AUTOSAR XML (schema 4-2-2)
package /ASW_COM_Package
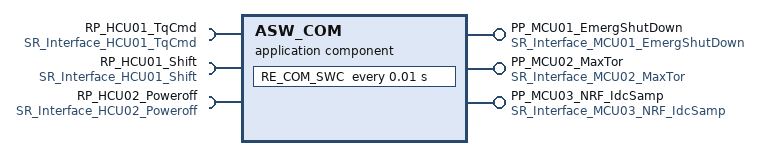
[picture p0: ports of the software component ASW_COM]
  application sw component type ASW_COM
    provide port PP_MCU01_EmergShutDown: provided-interface=SR_Interface_MCU01_EmergShutDown
    provide port PP_MCU02_MaxTor: provided-interface=SR_Interface_MCU02_MaxTor
    provide port PP_MCU03_NRF_IdcSamp: provided-interface=SR_Interface_MCU03_NRF_IdcSamp
    require port RP_HCU01_TqCmd: required-interface=SR_Interface_HCU01_TqCmd, nonqueued-receiver-com-spec{data-element=DE_TqCmd, alive-timeout=0.3}
    require port RP_HCU01_Shift: required-interface=SR_Interface_HCU01_Shift, nonqueued-receiver-com-spec{data-element=DE_Shift, alive-timeout=0.3}
    require port RP_HCU02_Poweroff: required-interface=SR_Interface_HCU02_Poweroff, nonqueued-receiver-com-spec{data-element=DE_Poweroff, alive-timeout=0.3}
    internal behavior IB_ASW_COM
      timing event TE_RE_COM_SWC_10ms: start-on-event=RE_COM_SWC, period=0.01
      runnable RE_COM_SWC: minimum-start-interval=0.01
        data-read-access:
          access VA_READ_HCU01_TqCmd: accessed-variable=RP_HCU01_TqCmd.DE_TqCmd
          access VA_READ_HCU01_Shift: accessed-variable=RP_HCU01_Shift.DE_Shift
          access VA_READ_HCU02_Poweroff: accessed-variable=RP_HCU02_Poweroff.DE_Poweroff
        data-write-access:
          access VA_WRITE_MCU01_EmergShutDown: accessed-variable=PP_MCU01_EmergShutDown.DE_EmergShutDown
          access VA_WRITE_MCU02_MaxTor: accessed-variable=PP_MCU02_MaxTor.DE_MaxTor
          access VA_WRITE_MCU03_NRF_IdcSamp: accessed-variable=PP_MCU03_NRF_IdcSamp.DE_IdcSamp
package /COM_Interface
  6 x sender receiver interface:
    SR_Interface_MCU01_EmergShutDown
      data DE_EmergShutDown: type=dt_boolean
    SR_Interface_MCU02_MaxTor
      data DE_MaxTor: type=dt_float32
    SR_Interface_MCU03_NRF_IdcSamp
      data DE_IdcSamp: type=dt_float32
    SR_Interface_HCU01_TqCmd
      data DE_TqCmd: type=dt_float32
    SR_Interface_HCU01_Shift
      data DE_Shift: type=dt_uint8
    SR_Interface_HCU02_Poweroff
      data DE_Poweroff: type=dt_boolean
package /DataTypes
  impl type dt_boolean: category=VALUE, base-type=boolean
  impl type dt_float32: category=VALUE, base-type=float32
  impl type dt_uint8: category=VALUE, base-type=uint8
